# STM32U599 register map
File version: 0.2
CPU: CM33 r0p1, little endian, MPU, FPU, 4 interrupt priority bits
Registers are 32-bit, read-write, reset 0x0 unless marked. A register's access mark holds for its fields unless they carry their own. Offsets are from the block's base; [hi:lo] are bit positions; 'fields as' and 'values as' point back to an identical list.

## SAI1 — Serial audio interface
Base 0x40015400
Same registers: SAI2 0x40015800, SEC_SAI1 0x50015400, SEC_SAI2 0x50015800
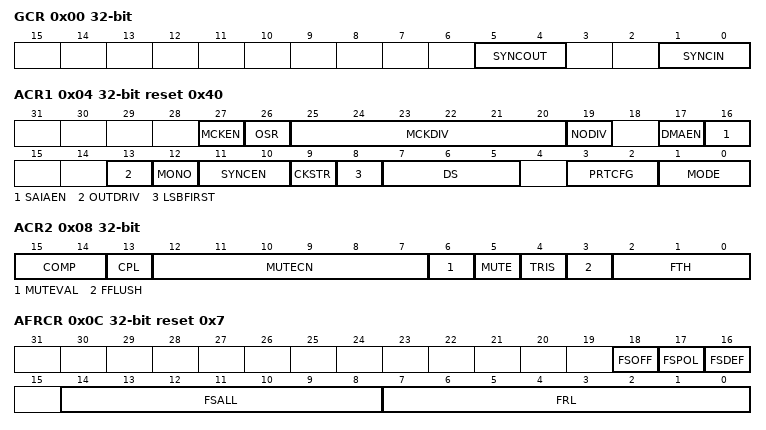
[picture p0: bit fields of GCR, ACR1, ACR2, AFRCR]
0x00 GCR — Global configuration register
  [5:4] SYNCOUT — Synchronization outputs
  [1:0] SYNCIN — Synchronization inputs
0x04 ACR1 reset 0x40 — A Configuration register 1
  [27] MCKEN
  [26] OSR
  [25:20] MCKDIV — Master clock divider
  [19] NODIV — No divider
  [17] DMAEN — DMA enable
  [16] SAIAEN — Audio block A enable
  [13] OUTDRIV — Output drive
  [12] MONO — Mono mode
  [11:10] SYNCEN — Synchronization enable
  [9] CKSTR — Clock strobing edge
  [8] LSBFIRST — Least significant bit first
  [7:5] DS — Data size
  [3:2] PRTCFG — Protocol configuration
  [1:0] MODE — Audio block mode
0x08 ACR2 — A Configuration register 2
  [15:14] COMP — Companding mode
  [13] CPL — Complement bit
  [12:7] MUTECN — Mute counter
  [6] MUTEVAL — Mute value
  [5] MUTE
  [4] TRIS — Tristate management on data line
  [3] FFLUSH — FIFO flush
  [2:0] FTH — FIFO threshold
0x0C AFRCR access per field reset 0x7 — A frame configuration register
  [18] FSOFF rw — Frame synchronization offset
  [17] FSPOL rw — Frame synchronization polarity
  [16] FSDEF ro — Frame synchronization definition
  [14:8] FSALL rw — Frame synchronization active level length
  [7:0] FRL rw — Frame length
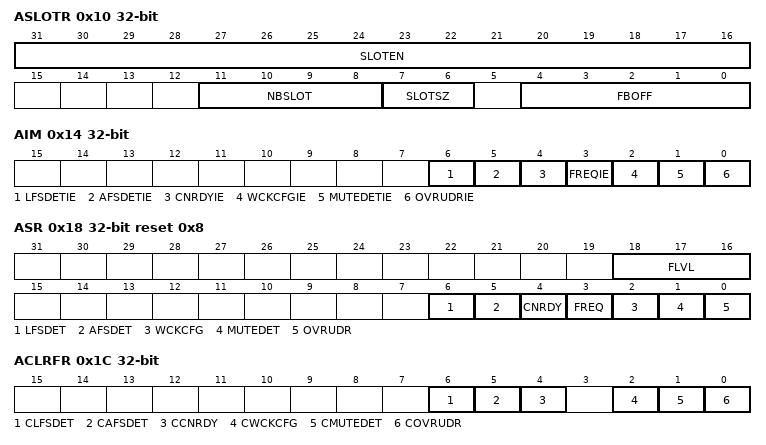
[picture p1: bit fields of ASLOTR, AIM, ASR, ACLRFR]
0x10 ASLOTR — A Slot register
  [31:16] SLOTEN — Slot enable
  [11:8] NBSLOT — Number of slots in an audio frame
  [7:6] SLOTSZ — Slot size
  [4:0] FBOFF — First bit offset
0x14 AIM — A Interrupt mask register
  [6] LFSDETIE — Late frame synchronization detection interrupt enable
  [5] AFSDETIE — Anticipated frame synchronization detection interrupt enable
  [4] CNRDYIE — Codec not ready interrupt enable
  [3] FREQIE — FIFO request interrupt enable
  [2] WCKCFGIE — Wrong clock configuration interrupt enable
  [1] MUTEDETIE — Mute detection interrupt enable
  [0] OVRUDRIE — Overrun/underrun interrupt enable
0x18 ASR ro reset 0x8 — A Status register
  [18:16] FLVL — FIFO level threshold
  [6] LFSDET — Late frame synchronization detection
  [5] AFSDET — Anticipated frame synchronization detection
  [4] CNRDY — Codec not ready
  [3] FREQ — FIFO request
  [2] WCKCFG — Wrong clock configuration flag. This bit is read only
  [1] MUTEDET — Mute detection
  [0] OVRUDR — Overrun / underrun
0x1C ACLRFR wo — A Clear flag register
  [6] CLFSDET — Clear late frame synchronization detection flag
  [5] CAFSDET — Clear anticipated frame synchronization detection flag
  [4] CCNRDY — Clear codec not ready flag
  [2] CWCKCFG — Clear wrong clock configuration flag
  [1] CMUTEDET — Mute detection flag
  [0] COVRUDR — Clear overrun / underrun
0x20 ADR — A Data register
  [31:0] DATA
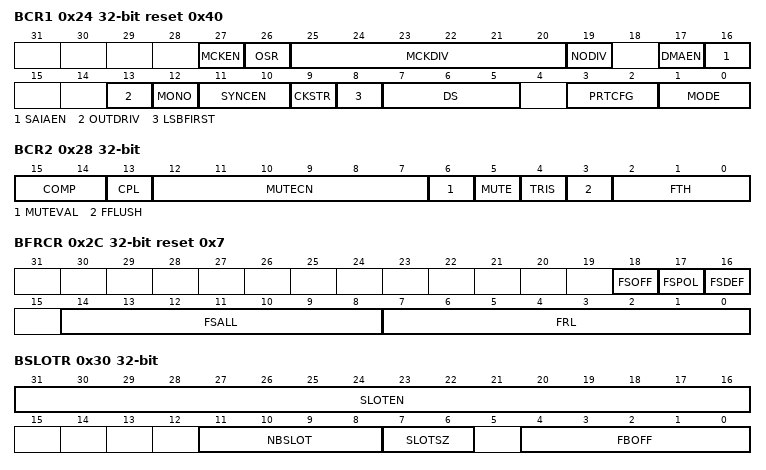
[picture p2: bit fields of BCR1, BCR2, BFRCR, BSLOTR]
0x24 BCR1 reset 0x40 — B Configuration register 1
  fields as ACR1
0x28 BCR2 — B Configuration register 2
  fields as ACR2
0x2C BFRCR access per field reset 0x7 — B frame configuration register
  fields as AFRCR
0x30 BSLOTR — B Slot register
  fields as ASLOTR
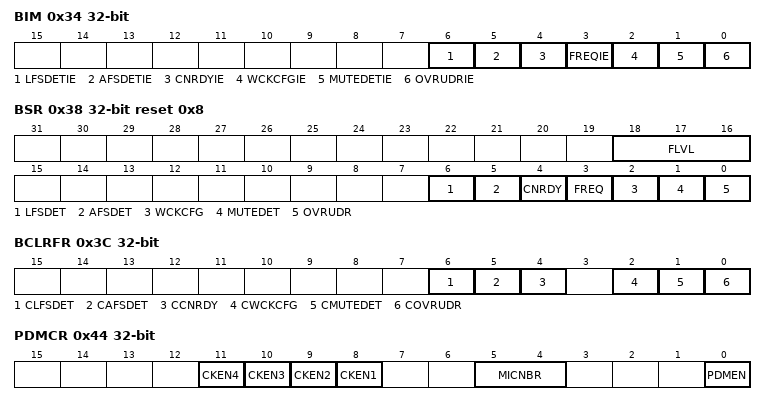
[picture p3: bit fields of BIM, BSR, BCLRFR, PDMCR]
0x34 BIM — B Interrupt mask register
  fields as AIM
0x38 BSR ro reset 0x8 — B Status register
  [18:16] FLVL — FIFO level threshold
  [6] LFSDET — Late frame synchronization detection
  [5] AFSDET — Anticipated frame synchronization detection
  [4] CNRDY — Codec not ready
  [3] FREQ — FIFO request
  [2] WCKCFG — Wrong clock configuration flag
  [1] MUTEDET — Mute detection
  [0] OVRUDR — Overrun / underrun
0x3C BCLRFR wo — B Clear flag register
  fields as ACLRFR
0x40 BDR — B Data register
  [31:0] DATA
0x44 PDMCR — PDM control register
  [11] CKEN4
  [10] CKEN3
  [9] CKEN2
  [8] CKEN1 — Clock enable of bitstream clock number 1
  [5:4] MICNBR
  [0] PDMEN — PDM enable
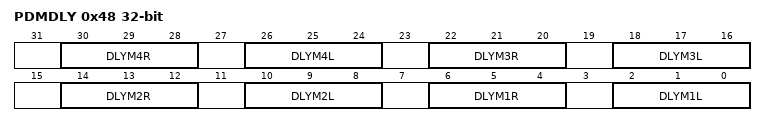
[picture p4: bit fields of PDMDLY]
0x48 PDMDLY — PDM delay register
  [30:28] DLYM4R
  [26:24] DLYM4L
  [22:20] DLYM3R
  [18:16] DLYM3L
  [14:12] DLYM2R — Delay line for second microphone of pair 2
  [10:8] DLYM2L — Delay line for first microphone of pair 2
  [6:4] DLYM1R — Delay line adjust for second microphone of pair 1
  [2:0] DLYM1L — Delay line adjust for first microphone of pair 1
